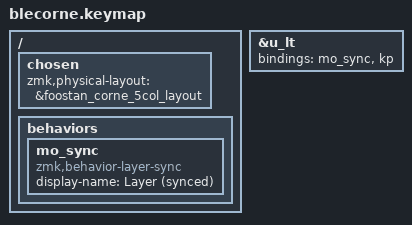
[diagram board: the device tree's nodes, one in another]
// Miryoku (QWERTY) for the Boardsource Wireless Corne SMT (blecorne).
// Miryoku: Copyright 2021 Manna Harbour, https://github.com/manna-harbour/miryoku
//
// Miryoku uses 36 keys: the 3x5 grid on each half plus the 3 thumb keys.
// The outer pinky columns are cut off, so this uses the 5-column (36-key) layout.
// Options (alphas, clipboard, nav style...) live in config/miryoku/custom_config.h.

#include "miryoku/custom_config.h"
#include "miryoku/mapping/36/corne_5col.h"
#include "miryoku/miryoku.dtsi"

/ {
    chosen {
        zmk,physical-layout = &foostan_corne_5col_layout;
    };
};

// Only the 36-key layout exists in this firmware. The board also defines the 42-key "6 Column"
// layout; with ZMK Studio the left half remembers which layout was last selected (also from
// older firmware), and a left half on 6 columns with a right half on 5 columns scrambles the
// right-hand keys. Removing the 6-column layout (and its position map) rules that out.
/delete-node/ &foostan_corne_6col_posmap;
/delete-node/ &foostan_corne_6col_layout;

// Layer holds on the thumbs (and Z / slash) use &mo_sync instead of &mo: it behaves the same,
// but also runs on the right half so its nice!view can show the held layer (see src/behaviors/).
/ {
    behaviors {
        mo_sync: mo_sync {   // node name must stay <= 8 characters (split behavior name limit)
            compatible = "zmk,behavior-layer-sync";
            #binding-cells = <1>;
            display-name = "Layer (synced)";
        };
    };
};

&u_lt {
    bindings = <&mo_sync>, <&kp>;
};
